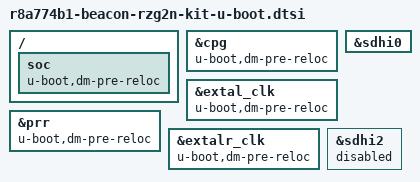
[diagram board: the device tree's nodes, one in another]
// SPDX-License-Identifier: GPL-2.0
/*
 * Copyright 2020 Compass Electronics Group, LLC
 */

/ {
	soc {
		u-boot,dm-pre-reloc;
	};
};

&cpg {
	u-boot,dm-pre-reloc;
};

&extal_clk {
	u-boot,dm-pre-reloc;
};

&prr {
	u-boot,dm-pre-reloc;
};

&extalr_clk {
	u-boot,dm-pre-reloc;
};

&sdhi0 {
	/delete-property/ cd-gpios;
};

&sdhi2 {
	status = "disabled";
};
